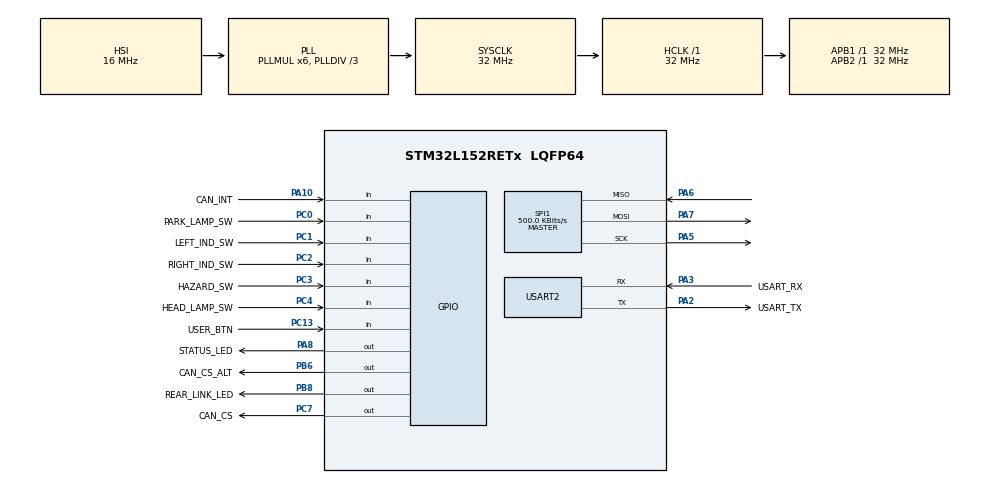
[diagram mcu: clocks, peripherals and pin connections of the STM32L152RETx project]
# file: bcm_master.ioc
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FREERTOS.Tasks01=defaultTask,24,128,StartDefaultTask,Default,NULL,Dynamic,NULL,NULL
FREERTOS.configCHECK_FOR_STACK_OVERFLOW=2
FREERTOS.configTOTAL_HEAP_SIZE=10240
FREERTOS.configUSE_NEWLIB_REENTRANT=1
FREERTOS.configUSE_TRACE_FACILITY=0
Mcu.Family=STM32L1
Mcu.Name=STM32L152RETx
Mcu.Package=LQFP64
NVIC.PriorityGroup=NVIC_PRIORITYGROUP_4
NVIC.TIM6_IRQn=true\:15\:0\:false\:false\:true\:false\:false\:true\:true
NVIC.TimeBase=TIM6_IRQn
NVIC.TimeBaseIP=TIM6
PA10.GPIO_Label=CAN_INT
PA10.Signal=GPIO_Input
PA13.GPIO_Label=TMS
PA13.Mode=Serial_Wire
PA13.Signal=SYS_JTMS-SWDIO
PA14.GPIO_Label=TCK
PA14.Mode=Serial_Wire
PA14.Signal=SYS_JTCK-SWCLK
PA2.GPIO_Label=USART_TX
PA2.Mode=Asynchronous
PA2.Signal=USART2_TX
PA3.GPIO_Label=USART_RX
PA3.Mode=Asynchronous
PA3.Signal=USART2_RX
PA5.Mode=Full_Duplex_Master
PA5.Signal=SPI1_SCK
PA6.Mode=Full_Duplex_Master
PA6.Signal=SPI1_MISO
PA7.Mode=Full_Duplex_Master
PA7.Signal=SPI1_MOSI
PA8.GPIO_Label=STATUS_LED
PA8.Signal=GPIO_Output
PB3.GPIO_Label=SWO
PB3.Signal=SYS_JTDO-TRACESWO
PB6.GPIO_Label=CAN_CS_ALT
PB6.GPIO_Speed=GPIO_SPEED_FREQ_MEDIUM
PB6.PinState=GPIO_PIN_SET
PB6.Signal=GPIO_Output
PB8.GPIO_Label=REAR_LINK_LED
PB8.Signal=GPIO_Output
PC0.GPIO_Label=PARK_LAMP_SW
PC0.GPIO_PuPd=GPIO_PULLUP
PC0.Signal=GPIO_Input
PC1.GPIO_Label=LEFT_IND_SW
PC1.GPIO_PuPd=GPIO_PULLUP
PC1.Signal=GPIO_Input
PC13-WKUP2.GPIO_Label=USER_BTN
PC13-WKUP2.Signal=GPIO_Input
PC14-OSC32_IN.Mode=LSE-External-Oscillator
PC14-OSC32_IN.Signal=RCC_OSC32_IN
PC15-OSC32_OUT.Mode=LSE-External-Oscillator
PC15-OSC32_OUT.Signal=RCC_OSC32_OUT
PC2.GPIO_Label=RIGHT_IND_SW
PC2.GPIO_PuPd=GPIO_PULLUP
PC2.Signal=GPIO_Input
PC3.GPIO_Label=HAZARD_SW
PC3.GPIO_PuPd=GPIO_PULLUP
PC3.Signal=GPIO_Input
PC4.GPIO_Label=HEAD_LAMP_SW
PC4.GPIO_PuPd=GPIO_PULLUP
PC4.Signal=GPIO_Input
PC7.GPIO_Label=CAN_CS
PC7.GPIO_PuPd=GPIO_NOPULL
PC7.GPIO_Speed=GPIO_SPEED_FREQ_MEDIUM
PC7.PinState=GPIO_PIN_SET
PC7.Signal=GPIO_Output
PH0-OSC_IN.Mode=HSE-External-Clock-Source
PH0-OSC_IN.Signal=RCC_OSC_IN
PH1-OSC_OUT.Signal=RCC_OSC_OUT
ProjectManager.HeapSize=0x200
ProjectManager.StackSize=0x400
ProjectManager.TargetToolchain=STM32CubeIDE
RCC.48MHZClocksFreq_Value=48000000
RCC.AHBFreq_Value=32000000
RCC.APB1Freq_Value=32000000
RCC.APB1TimFreq_Value=32000000
RCC.APB2Freq_Value=32000000
RCC.APB2TimFreq_Value=32000000
RCC.HCLKFreq_Value=32000000
RCC.HSE_VALUE=8000000
RCC.HSI_VALUE=16000000
RCC.MSI_VALUE=2097000
RCC.PLLDIV=RCC_PLL_DIV3
RCC.PLLMUL=RCC_PLL_MUL6
RCC.RTCClockSelectionVirtual=RCC_RTCCLKSOURCE_LSE
RCC.SYSCLKFreq_VALUE=32000000
RCC.SYSCLKSource=RCC_SYSCLKSOURCE_PLLCLK
RCC.USBOutput=48000000
RCC.VCOOutputFreq_Value=96000000
SPI1.BaudRatePrescaler=SPI_BAUDRATEPRESCALER_64
SPI1.CalculateBaudRate=500.0 KBits/s
SPI1.Direction=SPI_DIRECTION_2LINES
SPI1.Mode=SPI_MODE_MASTER
SPI1.VirtualType=VM_MASTER
USART2.VirtualMode=VM_ASYNC
VP_FREERTOS_VS_CMSIS_V2.Mode=CMSIS_V2
VP_SYS_VS_tim6.Mode=TIM6
board=NUCLEO-L152RE

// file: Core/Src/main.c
/* USER CODE BEGIN Header */
/**
  ******************************************************************************
  * @file           : main.c
  * @brief          : Main program body
  ******************************************************************************
  * @attention
  *
  * Copyright (c) 2026 STMicroelectronics.
  * All rights reserved.
  *
  * This software is licensed under terms that can be found in the LICENSE file
  * in the root directory of this software component.
  * If no LICENSE file comes with this software, it is provided AS-IS.
  *
  ******************************************************************************
  */
/* USER CODE END Header */
#include "main.h"
#include "cmsis_os.h"
#include "spi.h"
#include "usart.h"
#include "gpio.h"
#include "app_bcm.h"

void SystemClock_Config(void);
void MX_FREERTOS_Init(void);

int main(void)
{

  /* USER CODE BEGIN 1 */
	 HAL_Init();
	    SystemClock_Config();
	    MX_GPIO_Init();
	    MX_USART2_UART_Init();
	    MX_SPI1_Init();
	    AppBcm_Init();
	    AppBcm_Start();
	    for (;;)
	    {
	        AppBcm_RunCycle();
	    }
  /* USER CODE END 1 */

  /* MCU Configuration--------------------------------------------------------*/

  /* Reset of all peripherals, Initializes the Flash interface and the Systick. */
  HAL_Init();

  /* Configure the system clock */
  SystemClock_Config();

  /* Initialize all configured peripherals */
  MX_GPIO_Init();
  MX_USART2_UART_Init();
  MX_SPI1_Init();

  /* Init scheduler */
  osKernelInitialize();  /* Call init function for freertos objects (in cmsis_os2.c) */
  MX_FREERTOS_Init();

  /* Start scheduler */
  osKernelStart();

  /* We should never get here as control is now taken by the scheduler */

  /* Infinite loop */
  while (1)
  {

  }
}

void SystemClock_Config(void)
{
  RCC_OscInitTypeDef RCC_OscInitStruct = {0};
  RCC_ClkInitTypeDef RCC_ClkInitStruct = {0};

  /** Configure the main internal regulator output voltage
  */
  __HAL_PWR_VOLTAGESCALING_CONFIG(PWR_REGULATOR_VOLTAGE_SCALE1);

  /** Initializes the RCC Oscillators according to the specified parameters
  * in the RCC_OscInitTypeDef structure.
  */
  RCC_OscInitStruct.OscillatorType = RCC_OSCILLATORTYPE_HSI;
  RCC_OscInitStruct.HSIState = RCC_HSI_ON;
  RCC_OscInitStruct.HSICalibrationValue = RCC_HSICALIBRATION_DEFAULT;
  RCC_OscInitStruct.PLL.PLLState = RCC_PLL_ON;
  RCC_OscInitStruct.PLL.PLLSource = RCC_PLLSOURCE_HSI;
  RCC_OscInitStruct.PLL.PLLMUL = RCC_PLL_MUL6;
  RCC_OscInitStruct.PLL.PLLDIV = RCC_PLL_DIV3;
  if (HAL_RCC_OscConfig(&RCC_OscInitStruct) != HAL_OK)
  {
    Error_Handler();
  }

  /** Initializes the CPU, AHB and APB buses clocks
  */
  RCC_ClkInitStruct.ClockType = RCC_CLOCKTYPE_HCLK|RCC_CLOCKTYPE_SYSCLK
                              |RCC_CLOCKTYPE_PCLK1|RCC_CLOCKTYPE_PCLK2;
  RCC_ClkInitStruct.SYSCLKSource = RCC_SYSCLKSOURCE_PLLCLK;
  RCC_ClkInitStruct.AHBCLKDivider = RCC_SYSCLK_DIV1;
  RCC_ClkInitStruct.APB1CLKDivider = RCC_HCLK_DIV1;
  RCC_ClkInitStruct.APB2CLKDivider = RCC_HCLK_DIV1;

  if (HAL_RCC_ClockConfig(&RCC_ClkInitStruct, FLASH_LATENCY_1) != HAL_OK)
  {
    Error_Handler();
  }
}

void HAL_TIM_PeriodElapsedCallback(TIM_HandleTypeDef *htim)
{
  if (htim->Instance == TIM6)
  {
    HAL_IncTick();
  }
}

void Error_Handler(void)
{
  __disable_irq();
  while (1)
  {
  }
}

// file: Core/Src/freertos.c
/* USER CODE BEGIN Header */
/**
  ******************************************************************************
  * File Name          : freertos.c
  * Description        : Code for freertos applications
  ******************************************************************************
  * @attention
  *
  * Copyright (c) 2026 STMicroelectronics.
  * All rights reserved.
  *
  * This software is licensed under terms that can be found in the LICENSE file
  * in the root directory of this software component.
  * If no LICENSE file comes with this software, it is provided AS-IS.
  *
  ******************************************************************************
  */
/* USER CODE END Header */

#include "FreeRTOS.h"
#include "task.h"
#include "main.h"
#include "cmsis_os.h"

/* Definitions for defaultTask */
osThreadId_t defaultTaskHandle;
const osThreadAttr_t defaultTask_attributes = {
  .name = "defaultTask",
  .stack_size = 128 * 4,
  .priority = (osPriority_t) osPriorityNormal,
};

void StartDefaultTask(void *argument);

void MX_FREERTOS_Init(void); /* (MISRA C 2004 rule 8.1) */

/* Hook prototypes */
void vApplicationStackOverflowHook(xTaskHandle xTask, signed char *pcTaskName);

/* USER CODE BEGIN 4 */
void vApplicationStackOverflowHook(xTaskHandle xTask, signed char *pcTaskName)
{
   /* Run time stack overflow checking is performed if
   configCHECK_FOR_STACK_OVERFLOW is defined to 1 or 2. This hook function is
   called if a stack overflow is detected. */
}
/* USER CODE END 4 */

void MX_FREERTOS_Init(void) {

  /* Create the thread(s) */
  /* creation of defaultTask */
  defaultTaskHandle = osThreadNew(StartDefaultTask, NULL, &defaultTask_attributes);

}

void StartDefaultTask(void *argument)
{
  for(;;)
  {
    osDelay(1);
  }
}
